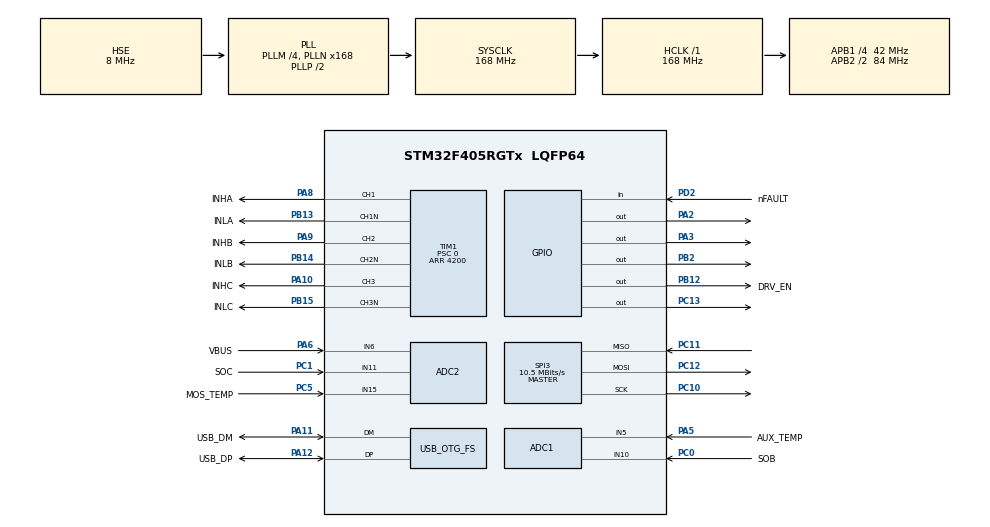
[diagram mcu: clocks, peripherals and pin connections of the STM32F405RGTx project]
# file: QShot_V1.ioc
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ADC1.Channel-0\#ChannelRegularConversion=ADC_CHANNEL_5
ADC1.Channel-1\#ChannelInjectedConversion=ADC_CHANNEL_10
ADC1.Channel-3\#ChannelRegularConversion=ADC_CHANNEL_TEMPSENSOR
ADC1.ClockPrescaler=ADC_CLOCK_SYNC_PCLK_DIV4
ADC1.ContinuousConvMode=DISABLE
ADC1.DMAContinuousRequests=DISABLE
ADC1.ExternalTrigConv=ADC_SOFTWARE_START
ADC1.ExternalTrigInjecConv=ADC_EXTERNALTRIGINJECCONV_T1_CC4
ADC1.InjNumberOfConversion=1
ADC1.InjectedOffset-1\#ChannelInjectedConversion=0
ADC1.InjectedRank-1\#ChannelInjectedConversion=1
ADC1.Mode=ADC_DUALMODE_REGSIMULT_INJECSIMULT
ADC1.NbrOfConversion=2
ADC1.NbrOfConversionFlag=1
ADC1.Rank-0\#ChannelRegularConversion=1
ADC1.Rank-3\#ChannelRegularConversion=2
ADC1.SamplingTime-0\#ChannelRegularConversion=ADC_SAMPLETIME_15CYCLES
ADC1.SamplingTime-1\#ChannelInjectedConversion=ADC_SAMPLETIME_15CYCLES
ADC1.SamplingTime-3\#ChannelRegularConversion=ADC_SAMPLETIME_15CYCLES
ADC1.ScanConvMode=ENABLE
ADC1.master=1
ADC2.Channel-0\#ChannelRegularConversion=ADC_CHANNEL_6
ADC2.Channel-1\#ChannelInjectedConversion=ADC_CHANNEL_11
ADC2.Channel-2\#ChannelRegularConversion=ADC_CHANNEL_15
ADC2.ClockPrescaler=ADC_CLOCK_SYNC_PCLK_DIV4
ADC2.DMAAccessMode=ADC_DMAACCESSMODE_2
ADC2.InjNumberOfConversion=1
ADC2.InjectedOffset-1\#ChannelInjectedConversion=0
ADC2.InjectedRank-1\#ChannelInjectedConversion=1
ADC2.Mode=ADC_DUALMODE_REGSIMULT_INJECSIMULT
ADC2.NbrOfConversion=2
ADC2.NbrOfConversionFlag=1
ADC2.Rank-0\#ChannelRegularConversion=1
ADC2.Rank-2\#ChannelRegularConversion=2
ADC2.SamplingTime-0\#ChannelRegularConversion=ADC_SAMPLETIME_15CYCLES
ADC2.SamplingTime-1\#ChannelInjectedConversion=ADC_SAMPLETIME_15CYCLES
ADC2.SamplingTime-2\#ChannelRegularConversion=ADC_SAMPLETIME_15CYCLES
ADC2.ScanConvMode=ENABLE
Dma.ADC1.0.Direction=DMA_PERIPH_TO_MEMORY
Dma.ADC1.0.FIFOMode=DMA_FIFOMODE_DISABLE
Dma.ADC1.0.Instance=DMA2_Stream0
Dma.ADC1.0.MemDataAlignment=DMA_MDATAALIGN_WORD
Dma.ADC1.0.MemInc=DMA_MINC_ENABLE
Dma.ADC1.0.Mode=DMA_CIRCULAR
Dma.ADC1.0.PeriphDataAlignment=DMA_PDATAALIGN_WORD
Dma.ADC1.0.PeriphInc=DMA_PINC_DISABLE
Dma.ADC1.0.Priority=DMA_PRIORITY_VERY_HIGH
Dma.Request0=ADC1
Mcu.Family=STM32F4
Mcu.Name=STM32F405RGTx
Mcu.Package=LQFP64
NVIC.ADC_IRQn=true\:0\:0\:false\:false\:true\:true\:true\:true
NVIC.DMA2_Stream0_IRQn=true\:0\:0\:false\:false\:true\:false\:true\:true
NVIC.OTG_FS_IRQn=true\:0\:0\:false\:false\:true\:false\:true\:true
NVIC.PriorityGroup=NVIC_PRIORITYGROUP_4
NVIC.TIM3_IRQn=true\:3\:0\:true\:false\:true\:true\:true\:true
PA10.GPIO_Label=INHC
PA10.Signal=S_TIM1_CH3
PA11.GPIO_Label=USB_DM
PA11.Mode=Device_Only
PA11.Signal=USB_OTG_FS_DM
PA12.GPIO_Label=USB_DP
PA12.Mode=Device_Only
PA12.Signal=USB_OTG_FS_DP
PA13.Mode=Serial_Wire
PA13.Signal=SYS_JTMS-SWDIO
PA14.Mode=Serial_Wire
PA14.Signal=SYS_JTCK-SWCLK
PA2.GPIO_ModeDefaultOutputPP=GPIO_MODE_OUTPUT_OD
PA2.GPIO_PuPd=GPIO_NOPULL
PA2.Signal=GPIO_Output
PA3.GPIO_ModeDefaultOutputPP=GPIO_MODE_OUTPUT_OD
PA3.GPIO_PuPd=GPIO_NOPULL
PA3.Signal=GPIO_Output
PA5.GPIO_Label=AUX_TEMP
PA5.Signal=ADCx_IN5
PA6.GPIO_Label=VBUS
PA6.Signal=ADCx_IN6
PA8.GPIO_Label=INHA
PA8.Signal=S_TIM1_CH1
PA9.GPIO_Label=INHB
PA9.Signal=S_TIM1_CH2
PB12.GPIO_Label=DRV_EN
PB12.Signal=GPIO_Output
PB13.GPIO_Label=INLA
PB13.Mode=PWM Generation1 CH1 CH1N
PB13.Signal=TIM1_CH1N
PB14.GPIO_Label=INLB
PB14.Mode=PWM Generation2 CH2 CH2N
PB14.Signal=TIM1_CH2N
PB15.GPIO_Label=INLC
PB15.Mode=PWM Generation3 CH3 CH3N
PB15.Signal=TIM1_CH3N
PB2.Signal=GPIO_Output
PC0.GPIO_Label=SOB
PC0.Signal=ADCx_IN10
PC1.GPIO_Label=SOC
PC1.Signal=ADCx_IN11
PC10.Mode=Full_Duplex_Master
PC10.Signal=SPI3_SCK
PC11.Mode=Full_Duplex_Master
PC11.Signal=SPI3_MISO
PC12.Mode=Full_Duplex_Master
PC12.Signal=SPI3_MOSI
PC13-ANTI_TAMP.Signal=GPIO_Output
PC5.GPIO_Label=MOS_TEMP
PC5.Signal=ADCx_IN15
PD2.GPIO_Label=nFAULT
PD2.Signal=GPIO_Input
PH0-OSC_IN.Mode=HSE-External-Oscillator
PH0-OSC_IN.Signal=RCC_OSC_IN
PH1-OSC_OUT.Mode=HSE-External-Oscillator
PH1-OSC_OUT.Signal=RCC_OSC_OUT
ProjectManager.HeapSize=0x200
ProjectManager.StackSize=0x400
ProjectManager.TargetToolchain=MDK-ARM V5.32
RCC.48MHZClocksFreq_Value=48000000
RCC.AHBFreq_Value=168000000
RCC.APB1CLKDivider=RCC_HCLK_DIV4
RCC.APB1Freq_Value=42000000
RCC.APB1TimFreq_Value=84000000
RCC.APB2CLKDivider=RCC_HCLK_DIV2
RCC.APB2Freq_Value=84000000
RCC.APB2TimFreq_Value=168000000
RCC.CortexFreq_Value=168000000
RCC.EnbaleCSS=true
RCC.HCLKFreq_Value=168000000
RCC.HSE_VALUE=8000000
RCC.HSI_VALUE=16000000
RCC.LSE_VALUE=32768
RCC.PLLM=4
RCC.PLLN=168
RCC.PLLQ=7
RCC.SYSCLKFreq_VALUE=168000000
RCC.SYSCLKSource=RCC_SYSCLKSOURCE_PLLCLK
RCC.VCOOutputFreq_Value=336000000
SH.ADCx_IN10.0=ADC1_IN10,IN10
SH.ADCx_IN11.0=ADC2_IN11,IN11
SH.ADCx_IN15.0=ADC2_IN15,IN15
SH.ADCx_IN5.0=ADC1_IN5,IN5
SH.ADCx_IN6.0=ADC2_IN6,IN6
SH.S_TIM1_CH1.0=TIM1_CH1,PWM Generation1 CH1 CH1N
SH.S_TIM1_CH2.0=TIM1_CH2,PWM Generation2 CH2 CH2N
SH.S_TIM1_CH3.0=TIM1_CH3,PWM Generation3 CH3 CH3N
SPI3.BaudRatePrescaler=SPI_BAUDRATEPRESCALER_4
SPI3.CLKPhase=SPI_PHASE_2EDGE
SPI3.CalculateBaudRate=10.5 MBits/s
SPI3.DataSize=SPI_DATASIZE_8BIT
SPI3.Direction=SPI_DIRECTION_2LINES
SPI3.Mode=SPI_MODE_MASTER
SPI3.VirtualType=VM_MASTER
TIM1.Channel-PWM\ Generation1\ CH1\ CH1N=TIM_CHANNEL_1
TIM1.Channel-PWM\ Generation2\ CH2\ CH2N=TIM_CHANNEL_2
TIM1.Channel-PWM\ Generation3\ CH3\ CH3N=TIM_CHANNEL_3
TIM1.Channel-PWM\ Generation4\ No\ Output=TIM_CHANNEL_4
TIM1.CounterMode=TIM_COUNTERMODE_CENTERALIGNED3
TIM1.OCMode_PWM-PWM\ Generation1\ CH1\ CH1N=TIM_OCMODE_PWM2
TIM1.OCMode_PWM-PWM\ Generation2\ CH2\ CH2N=TIM_OCMODE_PWM2
TIM1.OCMode_PWM-PWM\ Generation3\ CH3\ CH3N=TIM_OCMODE_PWM2
TIM1.OCMode_PWM-PWM\ Generation4\ No\ Output=TIM_OCMODE_PWM2
TIM1.Period=4200
TIM1.Prescaler=0
TIM1.Pulse-PWM\ Generation1\ CH1\ CH1N=2100
TIM1.Pulse-PWM\ Generation2\ CH2\ CH2N=2100
TIM1.Pulse-PWM\ Generation3\ CH3\ CH3N=2100
TIM1.Pulse-PWM\ Generation4\ No\ Output=1
TIM1.TIM_MasterOutputTrigger=TIM_TRGO_OC4REF
TIM3.Period=21000
TIM3.Prescaler=3
USB_DEVICE.CLASS_NAME_FS=CDC
USB_DEVICE.VirtualMode-CDC_FS=Cdc
USB_DEVICE.VirtualModeFS=Cdc_FS
USB_OTG_FS.VirtualMode=Device_Only
VP_ADC1_TempSens_Input.Mode=IN-TempSens
VP_TIM1_VS_ClockSourceINT.Mode=Internal
VP_TIM1_VS_no_output4.Mode=PWM Generation4 No Output
VP_TIM3_VS_ClockSourceINT.Mode=Internal
VP_USB_DEVICE_VS_USB_DEVICE_CDC_FS.Mode=CDC_FS
board=custom

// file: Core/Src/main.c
/* USER CODE BEGIN Header */
/**
  ******************************************************************************
  * @file           : main.c
  * @brief          : Main program body
  ******************************************************************************
  * @attention
  *
  * Copyright (c) 2026 STMicroelectronics.
  * All rights reserved.
  *
  * This software is licensed under terms that can be found in the LICENSE file
  * in the root directory of this software component.
  * If no LICENSE file comes with this software, it is provided AS-IS.
  *
  ******************************************************************************
  */
/* USER CODE END Header */
#include "main.h"
#include "adc.h"
#include "dma.h"
#include "spi.h"
#include "tim.h"
#include "usb_device.h"
#include "gpio.h"

/* USER CODE BEGIN Includes */
#include "APP_Control.h"
#include "host_comm.h"
/* USER CODE END Includes */

/* USER CODE BEGIN PV */
// user debug variables
extern MotorState_t AC_Motor_State;
volatile uint16_t Global_AS5600_Raw_Angle; // 在 main 的 while(1) 里更新
volatile uint16_t AS5600_Zero_Offset;      // 在 ROTOR_ALIGN 结束时记录
HostComm_Manager_t g_host_comm;
extern FOC_Core_t FOC_Core_CTS;
extern q16_t Target_RPM;
extern volatile int32_t g_motor_speed_rpm;
// user debug variables

/* USER CODE END PV */

void SystemClock_Config(void);

int main(void)
{

  /* MCU Configuration--------------------------------------------------------*/

  /* Reset of all peripherals, Initializes the Flash interface and the Systick. */
  HAL_Init();

  /* Configure the system clock */
  SystemClock_Config();

  /* Initialize all configured peripherals */
  MX_GPIO_Init();
  MX_DMA_Init();
  MX_TIM1_Init();
  MX_SPI3_Init();
  MX_ADC1_Init();
  MX_ADC2_Init();
  MX_TIM3_Init();
  MX_USB_DEVICE_Init();
  /* USER CODE BEGIN 2 */
  HostComm_Init(&g_host_comm, &FOC_Core_CTS, &g_motor_speed_rpm);

  //
  AC_MySystem_Init();

  /* USER CODE END 2 */

  /* Infinite loop */
  /* USER CODE BEGIN WHILE */
  while (1)
  {
//		// 1. 持续读取当前原始角度
//    uint16_t temp_angle = _ME_AS5600_Read_Raw_Angle();
    HostComm_Main_Process(&g_host_comm);
//    // 只有读到的不是错误值（0xFFFF）时才更新全局变量
//    if(temp_angle != 0xFFFF) {
//        Global_AS5600_Raw_Angle = temp_angle;
//	}
//}

    /* USER CODE END WHILE */

  }
}

void SystemClock_Config(void)
{
  RCC_OscInitTypeDef RCC_OscInitStruct = {0};
  RCC_ClkInitTypeDef RCC_ClkInitStruct = {0};

  /** Configure the main internal regulator output voltage
  */
  __HAL_RCC_PWR_CLK_ENABLE();
  __HAL_PWR_VOLTAGESCALING_CONFIG(PWR_REGULATOR_VOLTAGE_SCALE1);

  /** Initializes the RCC Oscillators according to the specified parameters
  * in the RCC_OscInitTypeDef structure.
  */
  RCC_OscInitStruct.OscillatorType = RCC_OSCILLATORTYPE_HSE;
  RCC_OscInitStruct.HSEState = RCC_HSE_ON;
  RCC_OscInitStruct.PLL.PLLState = RCC_PLL_ON;
  RCC_OscInitStruct.PLL.PLLSource = RCC_PLLSOURCE_HSE;
  RCC_OscInitStruct.PLL.PLLM = 4;
  RCC_OscInitStruct.PLL.PLLN = 168;
  RCC_OscInitStruct.PLL.PLLP = RCC_PLLP_DIV2;
  RCC_OscInitStruct.PLL.PLLQ = 7;
  if (HAL_RCC_OscConfig(&RCC_OscInitStruct) != HAL_OK)
  {
    Error_Handler();
  }

  /** Initializes the CPU, AHB and APB buses clocks
  */
  RCC_ClkInitStruct.ClockType = RCC_CLOCKTYPE_HCLK|RCC_CLOCKTYPE_SYSCLK
                              |RCC_CLOCKTYPE_PCLK1|RCC_CLOCKTYPE_PCLK2;
  RCC_ClkInitStruct.SYSCLKSource = RCC_SYSCLKSOURCE_PLLCLK;
  RCC_ClkInitStruct.AHBCLKDivider = RCC_SYSCLK_DIV1;
  RCC_ClkInitStruct.APB1CLKDivider = RCC_HCLK_DIV4;
  RCC_ClkInitStruct.APB2CLKDivider = RCC_HCLK_DIV2;

  if (HAL_RCC_ClockConfig(&RCC_ClkInitStruct, FLASH_LATENCY_5) != HAL_OK)
  {
    Error_Handler();
  }

  /** Enables the Clock Security System
  */
  HAL_RCC_EnableCSS();
}

void Error_Handler(void)
{
  __disable_irq();
  while (1)
  {
  }
}
